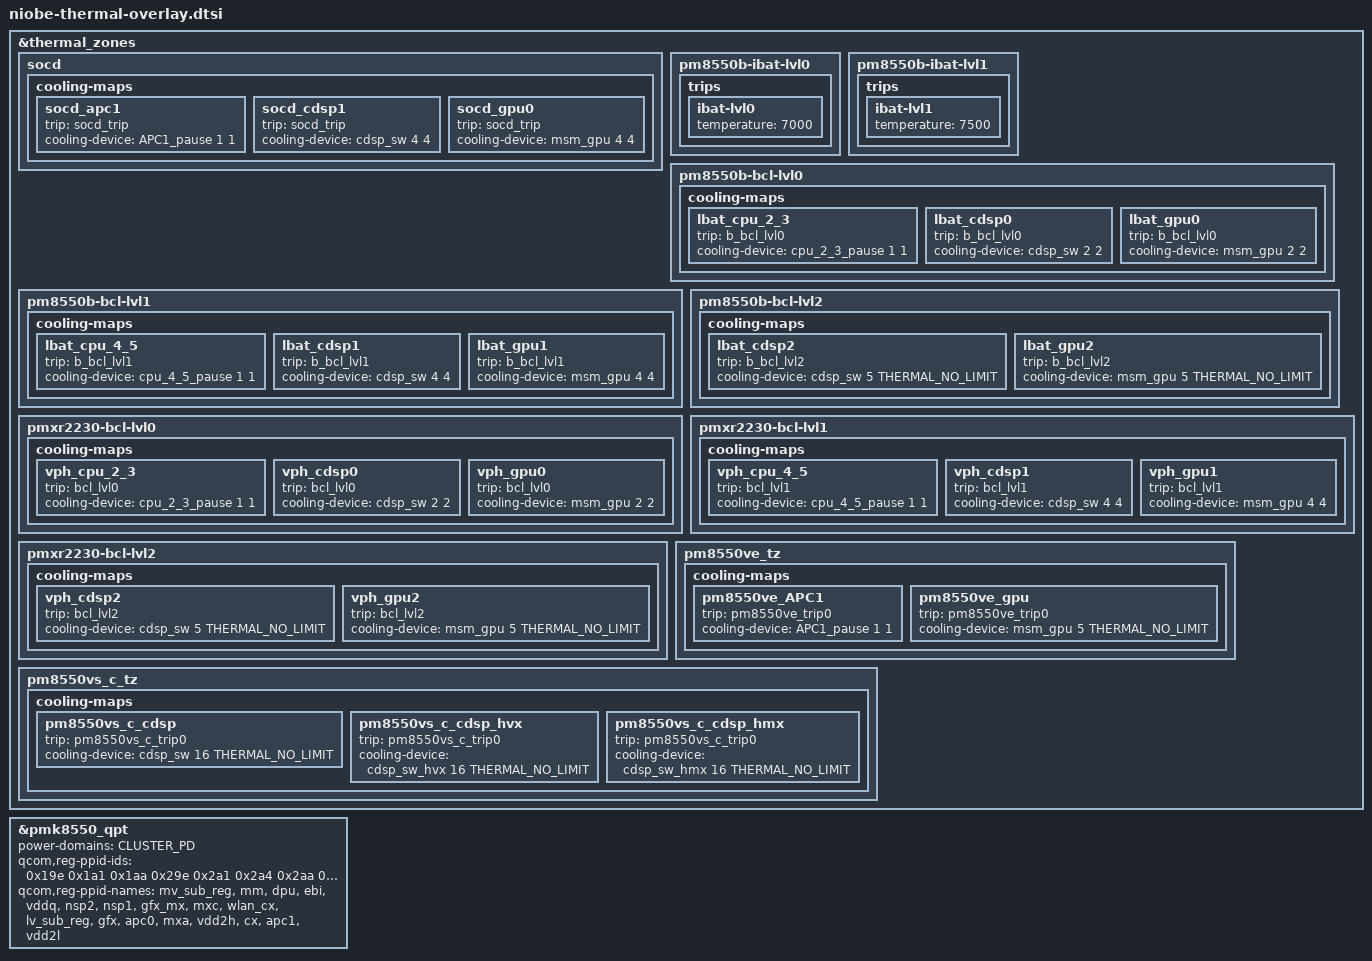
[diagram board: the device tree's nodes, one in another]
#include <dt-bindings/thermal/thermal_qti.h>

&thermal_zones {
	socd {
		cooling-maps {
			socd_apc1 {
				trip = <&socd_trip>;
				cooling-device = <&APC1_pause 1 1>;
			};

			socd_cdsp1 {
				trip = <&socd_trip>;
				cooling-device = <&cdsp_sw 4 4>;
			};

			socd_gpu0 {
				trip = <&socd_trip>;
				cooling-device = <&msm_gpu 4 4>;
			};
		};
	};

	pm8550b-ibat-lvl0 {
		trips {
			ibat-lvl0 {
				temperature = <7000>;
			};
		};
	};

	pm8550b-ibat-lvl1 {
		trips {
			ibat-lvl1 {
				temperature = <7500>;
			};
		};
	};

	pm8550b-bcl-lvl0 {
		cooling-maps {
			lbat_cpu_2_3 {
				trip = <&b_bcl_lvl0>;
				cooling-device = <&cpu_2_3_pause 1 1>;
			};

			lbat_cdsp0 {
				trip = <&b_bcl_lvl0>;
				cooling-device = <&cdsp_sw 2 2>;
			};

			lbat_gpu0 {
				trip = <&b_bcl_lvl0>;
				cooling-device = <&msm_gpu 2 2>;
			};
		};
	};

	pm8550b-bcl-lvl1 {
		cooling-maps {
			lbat_cpu_4_5 {
				trip = <&b_bcl_lvl1>;
				cooling-device = <&cpu_4_5_pause 1 1>;
			};

			lbat_cdsp1 {
				trip = <&b_bcl_lvl1>;
				cooling-device = <&cdsp_sw 4 4>;
			};

			lbat_gpu1 {
				trip = <&b_bcl_lvl1>;
				cooling-device = <&msm_gpu 4 4>;
			};
		};
	};

	pm8550b-bcl-lvl2 {
		cooling-maps {
			lbat_cdsp2 {
				trip = <&b_bcl_lvl2>;
				cooling-device = <&cdsp_sw 5 THERMAL_NO_LIMIT>;
			};

			lbat_gpu2 {
				trip = <&b_bcl_lvl2>;
				cooling-device = <&msm_gpu 5 THERMAL_NO_LIMIT>;
			};
		};
	};

	pmxr2230-bcl-lvl0 {
		cooling-maps {
			vph_cpu_2_3 {
				trip = <&bcl_lvl0>;
				cooling-device = <&cpu_2_3_pause 1 1>;
			};

			vph_cdsp0 {
				trip = <&bcl_lvl0>;
				cooling-device = <&cdsp_sw 2 2>;
			};

			vph_gpu0 {
				trip = <&bcl_lvl0>;
				cooling-device = <&msm_gpu 2 2>;
			};
		};
	};

	pmxr2230-bcl-lvl1 {
		cooling-maps {
			vph_cpu_4_5 {
				trip = <&bcl_lvl1>;
				cooling-device = <&cpu_4_5_pause 1 1>;
			};

			vph_cdsp1 {
				trip = <&bcl_lvl1>;
				cooling-device = <&cdsp_sw 4 4>;
			};

			vph_gpu1 {
				trip = <&bcl_lvl1>;
				cooling-device = <&msm_gpu 4 4>;
			};
		};
	};

	pmxr2230-bcl-lvl2 {
		cooling-maps {
			vph_cdsp2 {
				trip = <&bcl_lvl2>;
				cooling-device = <&cdsp_sw 5 THERMAL_NO_LIMIT>;
			};

			vph_gpu2 {
				trip = <&bcl_lvl2>;
				cooling-device = <&msm_gpu 5 THERMAL_NO_LIMIT>;
			};
		};
	};

	pm8550ve_tz {
		cooling-maps {
			pm8550ve_APC1 {
				trip = <&pm8550ve_trip0>;
				cooling-device = <&APC1_pause 1 1>;
			};

			pm8550ve_gpu {
				trip = <&pm8550ve_trip0>;
				cooling-device = <&msm_gpu 5 THERMAL_NO_LIMIT>;
			};
		};
	};

	pm8550vs_c_tz {
		cooling-maps {
			pm8550vs_c_cdsp {
				trip = <&pm8550vs_c_trip0>;
				cooling-device = <&cdsp_sw 16 THERMAL_NO_LIMIT>;
			};

			pm8550vs_c_cdsp_hvx {
				trip = <&pm8550vs_c_trip0>;
				cooling-device = <&cdsp_sw_hvx 16 THERMAL_NO_LIMIT>;
			};

			pm8550vs_c_cdsp_hmx {
				trip = <&pm8550vs_c_trip0>;
				cooling-device = <&cdsp_sw_hmx 16 THERMAL_NO_LIMIT>;
			};
		};
	};
};

&pmk8550_qpt {
	status = "okay";
	power-domains = <&CLUSTER_PD>;
	qcom,reg-ppid-ids = /bits/ 16 <0x19e 0x1a1 0x1aa
			0x29e 0x2a1 0x2a4 0x2aa 0x3a1 0x3a4 0x3a7 0x3aa
			0x3ad 0x59b 0x5a1 0x5a4 0x5aa 0x5ad 0x5a7>;

	qcom,reg-ppid-names = "mv_sub_reg",
			"mm", "dpu", "ebi", "vddq", "nsp2", "nsp1",
			"gfx_mx", "mxc", "wlan_cx", "lv_sub_reg",
			"gfx", "apc0", "mxa", "vdd2h", "cx", "apc1",
			"vdd2l";
};
